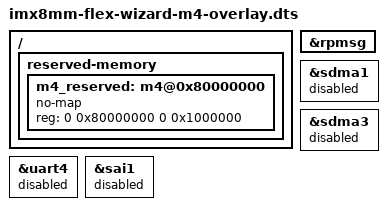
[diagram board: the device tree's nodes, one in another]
/dts-v1/;
/plugin/;

/ {
	fragment@0 {
		target-path = "/";
		__overlay__ {
			reserved-memory {
				#address-cells = <2>;
				#size-cells = <2>;
				m4_reserved: m4@0x80000000 {
					no-map;
					reg = <0 0x80000000 0 0x1000000>;
				};
			};
		};
	};
	/*
	* ATTENTION: M4 may use IPs like below
	* ECSPI0/ECSPI2, GPIO1/GPIO5, GPT1, I2S1, WDOG1, UART4, PWM3, SDMA1
	*/

	fragment@1 {
		target = <&rpmsg>;
		__overlay__ {
			status = "okay";
		};
	};

	fragment@2 {
		target = <&sdma1>;
		__overlay__ {
			status = "disabled";
		};
	};

	fragment@3 {
		target = <&sdma3>;
		__overlay__ {
			status = "disabled";
		};
	};

	fragment@4 {
		target = <&uart4>;
		__overlay__ {
			status = "disabled";
		};
	};

	fragment@5 {
		target = <&sai1>;
		__overlay__ {
			status = "disabled";
		};
	};
};
